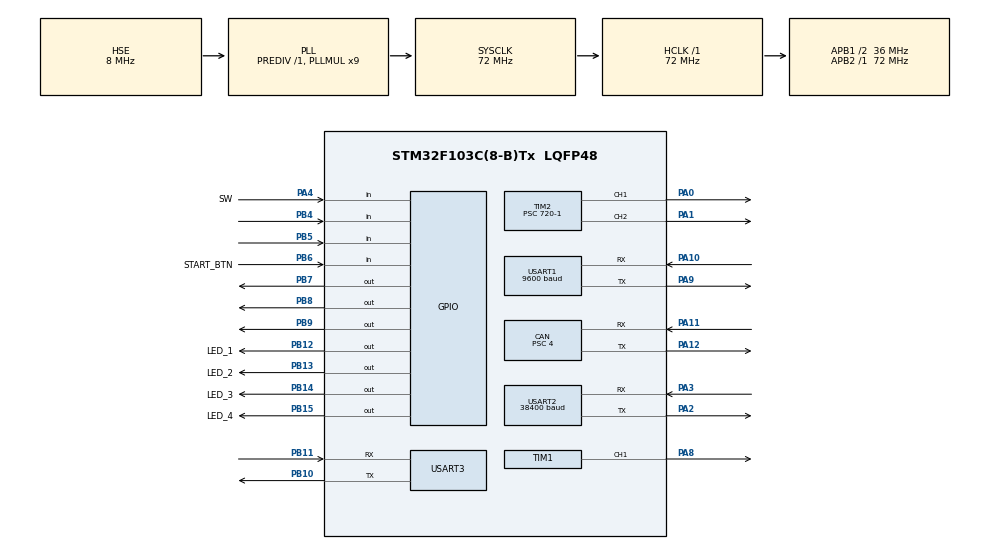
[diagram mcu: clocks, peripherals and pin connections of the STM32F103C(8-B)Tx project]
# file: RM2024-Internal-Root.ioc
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CAN.ABOM=ENABLE
CAN.BS1=CAN_BS1_6TQ
CAN.BS2=CAN_BS2_2TQ
CAN.CalculateBaudRate=1000000
CAN.CalculateTimeBit=1000
CAN.CalculateTimeQuantum=111.11111111111111
CAN.Prescaler=4
Dma.Request0=USART1_RX
Dma.Request1=USART3_RX
Dma.Request2=USART3_TX
Dma.USART1_RX.0.Direction=DMA_PERIPH_TO_MEMORY
Dma.USART1_RX.0.Instance=DMA1_Channel5
Dma.USART1_RX.0.MemDataAlignment=DMA_MDATAALIGN_BYTE
Dma.USART1_RX.0.MemInc=DMA_MINC_ENABLE
Dma.USART1_RX.0.Mode=DMA_NORMAL
Dma.USART1_RX.0.PeriphDataAlignment=DMA_PDATAALIGN_BYTE
Dma.USART1_RX.0.PeriphInc=DMA_PINC_DISABLE
Dma.USART1_RX.0.Priority=DMA_PRIORITY_HIGH
Dma.USART3_RX.1.Direction=DMA_PERIPH_TO_MEMORY
Dma.USART3_RX.1.Instance=DMA1_Channel3
Dma.USART3_RX.1.MemDataAlignment=DMA_MDATAALIGN_BYTE
Dma.USART3_RX.1.MemInc=DMA_MINC_ENABLE
Dma.USART3_RX.1.Mode=DMA_NORMAL
Dma.USART3_RX.1.PeriphDataAlignment=DMA_PDATAALIGN_BYTE
Dma.USART3_RX.1.PeriphInc=DMA_PINC_DISABLE
Dma.USART3_RX.1.Priority=DMA_PRIORITY_HIGH
Dma.USART3_TX.2.Direction=DMA_MEMORY_TO_PERIPH
Dma.USART3_TX.2.Instance=DMA1_Channel2
Dma.USART3_TX.2.MemDataAlignment=DMA_MDATAALIGN_BYTE
Dma.USART3_TX.2.MemInc=DMA_MINC_ENABLE
Dma.USART3_TX.2.Mode=DMA_NORMAL
Dma.USART3_TX.2.PeriphDataAlignment=DMA_PDATAALIGN_BYTE
Dma.USART3_TX.2.PeriphInc=DMA_PINC_DISABLE
Dma.USART3_TX.2.Priority=DMA_PRIORITY_HIGH
Mcu.Family=STM32F1
Mcu.Name=STM32F103C(8-B)Tx
Mcu.Package=LQFP48
NVIC.CAN1_RX1_IRQn=true\:10\:0\:true\:false\:true\:true\:true\:true
NVIC.CAN1_SCE_IRQn=true\:10\:0\:true\:false\:true\:true\:true\:true
NVIC.DMA1_Channel2_IRQn=true\:10\:0\:true\:false\:true\:false\:true\:true
NVIC.DMA1_Channel3_IRQn=true\:10\:0\:true\:false\:true\:false\:true\:true
NVIC.DMA1_Channel5_IRQn=true\:10\:0\:true\:false\:true\:false\:true\:true
NVIC.PriorityGroup=NVIC_PRIORITYGROUP_4
NVIC.TIM2_IRQn=true\:10\:0\:true\:false\:true\:true\:true\:true
NVIC.TIM4_IRQn=true\:5\:0\:true\:false\:true\:false\:true\:true
NVIC.TimeBase=TIM4_IRQn
NVIC.TimeBaseIP=TIM4
NVIC.USART1_IRQn=true\:10\:0\:true\:false\:true\:true\:true\:true
NVIC.USART2_IRQn=true\:0\:0\:false\:false\:true\:true\:true\:true
NVIC.USART3_IRQn=true\:10\:0\:true\:false\:true\:true\:true\:true
NVIC.USB_LP_CAN1_RX0_IRQn=true\:10\:0\:true\:false\:true\:true\:true\:true
PA0-WKUP.Signal=S_TIM2_CH1_ETR
PA1.Signal=S_TIM2_CH2
PA10.Mode=Asynchronous
PA10.Signal=USART1_RX
PA11.Mode=CAN_Activate
PA11.Signal=CAN_RX
PA12.Mode=CAN_Activate
PA12.Signal=CAN_TX
PA13.Mode=Serial_Wire
PA13.Signal=SYS_JTMS-SWDIO
PA14.Mode=Serial_Wire
PA14.Signal=SYS_JTCK-SWCLK
PA2.Mode=Asynchronous
PA2.Signal=USART2_TX
PA3.Mode=Asynchronous
PA3.Signal=USART2_RX
PA4.GPIO_Label=SW
PA4.Signal=GPIO_Input
PA8.Signal=S_TIM1_CH1
PA9.Mode=Asynchronous
PA9.Signal=USART1_TX
PB10.Mode=Asynchronous
PB10.Signal=USART3_TX
PB11.Mode=Asynchronous
PB11.Signal=USART3_RX
PB12.GPIO_Label=LED_1
PB12.Signal=GPIO_Output
PB13.GPIO_Label=LED_2
PB13.Signal=GPIO_Output
PB14.GPIO_Label=LED_3
PB14.Signal=GPIO_Output
PB15.GPIO_Label=LED_4
PB15.Signal=GPIO_Output
PB4.Signal=GPIO_Input
PB5.Signal=GPIO_Input
PB6.GPIO_Label=START_BTN
PB6.GPIO_PuPd=GPIO_PULLUP
PB6.Signal=GPIO_Input
PB7.Signal=GPIO_Output
PB8.Signal=GPIO_Output
PB9.Signal=GPIO_Output
PD0-OSC_IN.Mode=HSE-External-Oscillator
PD0-OSC_IN.Signal=RCC_OSC_IN
PD1-OSC_OUT.Mode=HSE-External-Oscillator
PD1-OSC_OUT.Signal=RCC_OSC_OUT
ProjectManager.HeapSize=0x200
ProjectManager.StackSize=0x400
ProjectManager.TargetToolchain=Makefile
RCC.AHBFreq_Value=72000000
RCC.APB1CLKDivider=RCC_HCLK_DIV2
RCC.APB1Freq_Value=36000000
RCC.APB1TimFreq_Value=72000000
RCC.APB2Freq_Value=72000000
RCC.APB2TimFreq_Value=72000000
RCC.HCLKFreq_Value=72000000
RCC.PLLMUL=RCC_PLL_MUL9
RCC.PLLSourceVirtual=RCC_PLLSOURCE_HSE
RCC.SYSCLKFreq_VALUE=72000000
RCC.SYSCLKSource=RCC_SYSCLKSOURCE_PLLCLK
RCC.USBFreq_Value=72000000
SH.S_TIM1_CH1.0=TIM1_CH1,PWM Generation1 CH1
SH.S_TIM2_CH1_ETR.0=TIM2_CH1,PWM Generation1 CH1
SH.S_TIM2_CH2.0=TIM2_CH2,PWM Generation2 CH2
TIM1.AutoReloadPreload=TIM_AUTORELOAD_PRELOAD_ENABLE
TIM1.Channel-PWM\ Generation1\ CH1=TIM_CHANNEL_1
TIM2.Channel-PWM\ Generation1\ CH1=TIM_CHANNEL_1
TIM2.Channel-PWM\ Generation2\ CH2=TIM_CHANNEL_2
TIM2.Period=2000-1
TIM2.Prescaler=720-1
USART1.BaudRate=9600
USART1.Mode=MODE_TX_RX
USART1.Parity=PARITY_NONE
USART1.VirtualMode=VM_ASYNC
USART1.WordLength=WORDLENGTH_8B
USART2.BaudRate=38400
USART2.Parity=PARITY_NONE
USART2.VirtualMode=VM_ASYNC
USART3.VirtualMode=VM_ASYNC
VP_SYS_VS_tim4.Mode=TIM4
VP_TIM2_VS_ClockSourceINT.Mode=Internal
board=custom

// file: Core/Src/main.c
/* USER CODE BEGIN Header */
/**
  ******************************************************************************
  * @file           : main.c
  * @brief          : Main program body
  ******************************************************************************
  * @attention
  *
  * Copyright (c) 2023 STMicroelectronics.
  * All rights reserved.
  *
  * This software is licensed under terms that can be found in the LICENSE file
  * in the root directory of this software component.
  * If no LICENSE file comes with this software, it is provided AS-IS.
  *
  ******************************************************************************
  */
/* USER CODE END Header */
#include "main.h"
#include "can.h"
#include "dma.h"
#include "tim.h"
#include "usart.h"
#include "gpio.h"

/* USER CODE BEGIN PV */
// static uint8_t buffer[1] = {0};
// static uint8_t ballError;
/* USER CODE END PV */

void SystemClock_Config(void);

int main(void)
{

  /* MCU Configuration--------------------------------------------------------*/

  /* Reset of all peripherals, Initializes the Flash interface and the Systick. */
  HAL_Init();

  /* Configure the system clock */
  SystemClock_Config();

  /* Initialize all configured peripherals */
  MX_GPIO_Init();
  MX_DMA_Init();
  MX_CAN_Init();
  MX_TIM1_Init();
  MX_USART1_UART_Init();
  MX_USART2_UART_Init();
  MX_USART3_UART_Init();
  MX_TIM2_Init();
  /* USER CODE BEGIN 2 */
  //HAL_UART_Receive_IT(&huart1,buffer,1);
  extern void startRTOS(void);
  startRTOS();
  /* USER CODE END 2 */

  /* Infinite loop */
  while (1)
  {

  }
}

void SystemClock_Config(void)
{
  RCC_OscInitTypeDef RCC_OscInitStruct = {0};
  RCC_ClkInitTypeDef RCC_ClkInitStruct = {0};

  /** Initializes the RCC Oscillators according to the specified parameters
  * in the RCC_OscInitTypeDef structure.
  */
  RCC_OscInitStruct.OscillatorType = RCC_OSCILLATORTYPE_HSE;
  RCC_OscInitStruct.HSEState = RCC_HSE_ON;
  RCC_OscInitStruct.HSEPredivValue = RCC_HSE_PREDIV_DIV1;
  RCC_OscInitStruct.HSIState = RCC_HSI_ON;
  RCC_OscInitStruct.PLL.PLLState = RCC_PLL_ON;
  RCC_OscInitStruct.PLL.PLLSource = RCC_PLLSOURCE_HSE;
  RCC_OscInitStruct.PLL.PLLMUL = RCC_PLL_MUL9;
  if (HAL_RCC_OscConfig(&RCC_OscInitStruct) != HAL_OK)
  {
    Error_Handler();
  }

  /** Initializes the CPU, AHB and APB buses clocks
  */
  RCC_ClkInitStruct.ClockType = RCC_CLOCKTYPE_HCLK|RCC_CLOCKTYPE_SYSCLK
                              |RCC_CLOCKTYPE_PCLK1|RCC_CLOCKTYPE_PCLK2;
  RCC_ClkInitStruct.SYSCLKSource = RCC_SYSCLKSOURCE_PLLCLK;
  RCC_ClkInitStruct.AHBCLKDivider = RCC_SYSCLK_DIV1;
  RCC_ClkInitStruct.APB1CLKDivider = RCC_HCLK_DIV2;
  RCC_ClkInitStruct.APB2CLKDivider = RCC_HCLK_DIV1;

  if (HAL_RCC_ClockConfig(&RCC_ClkInitStruct, FLASH_LATENCY_2) != HAL_OK)
  {
    Error_Handler();
  }
}

void HAL_TIM_PeriodElapsedCallback(TIM_HandleTypeDef *htim)
{
  if (htim->Instance == TIM4) {
    HAL_IncTick();
  }
}

void Error_Handler(void)
{
  __disable_irq();
  while (1)
  {
  }
}
